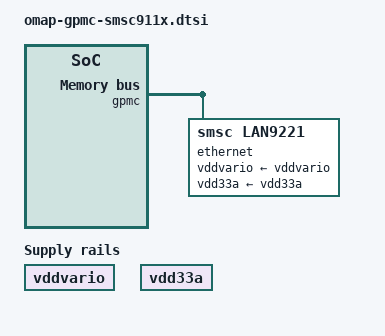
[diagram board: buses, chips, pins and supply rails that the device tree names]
// SPDX-License-Identifier: GPL-2.0
/*
 * Common file for GPMC connected smsc911x on omaps
 *
 * Note that the board specifc DTS file needs to specify
 * ranges, pinctrl, reg, interrupt parent and interrupts.
 */

/ {
	vddvario: regulator-vddvario {
		  compatible = "regulator-fixed";
		  regulator-name = "vddvario";
		  regulator-always-on;
	};

	vdd33a: regulator-vdd33a {
		compatible = "regulator-fixed";
		regulator-name = "vdd33a";
		regulator-always-on;
	};
};

&gpmc {
	ethernet@gpmc {
		compatible = "smsc,lan9221", "smsc,lan9115";
		bank-width = <2>;
		gpmc,device-width = <1>;
		gpmc,cycle2cycle-samecsen;
		gpmc,cycle2cycle-diffcsen;
		gpmc,cs-on-ns = <5>;
		gpmc,cs-rd-off-ns = <150>;
		gpmc,cs-wr-off-ns = <150>;
		gpmc,adv-on-ns = <0>;
		gpmc,adv-rd-off-ns = <15>;
		gpmc,adv-wr-off-ns = <40>;
		gpmc,oe-on-ns = <45>;
		gpmc,oe-off-ns = <140>;
		gpmc,we-on-ns = <45>;
		gpmc,we-off-ns = <140>;
		gpmc,rd-cycle-ns = <155>;
		gpmc,wr-cycle-ns = <155>;
		gpmc,access-ns = <120>;
		gpmc,page-burst-access-ns = <20>;
		gpmc,bus-turnaround-ns = <75>;
		gpmc,cycle2cycle-delay-ns = <75>;
		gpmc,wait-monitoring-ns = <0>;
		gpmc,clk-activation-ns = <0>;
		gpmc,wr-data-mux-bus-ns = <0>;
		gpmc,wr-access-ns = <0>;
		vddvario-supply = <&vddvario>;
		vdd33a-supply = <&vdd33a>;
		reg-io-width = <4>;
		smsc,save-mac-address;
	};
};
